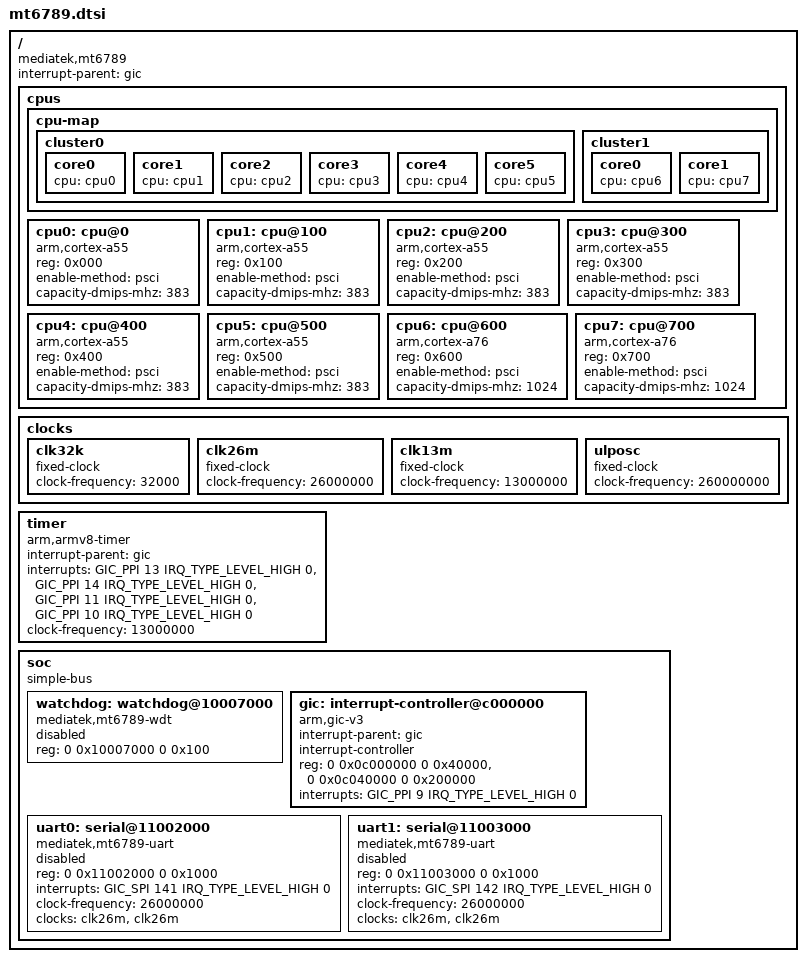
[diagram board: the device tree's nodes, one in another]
//SPDX-License-Identifier: (GPL-2.0)
/*
 * Copyright (C) 2024 Arseniy Velikanov
 */

#include <dt-bindings/interrupt-controller/irq.h>
#include <dt-bindings/interrupt-controller/arm-gic.h>

/ {
	compatible = "mediatek,mt6789";
	interrupt-parent = <&gic>;
	#address-cells = <2>;
	#size-cells = <2>;

	cpus {
		#address-cells = <1>;
		#size-cells = <0>;

		cpu-map {
			cluster0 {
				core0 {
					cpu = <&cpu0>;
				};
				core1 {
					cpu = <&cpu1>;
				};
				core2 {
					cpu = <&cpu2>;
				};
				core3 {
					cpu = <&cpu3>;
				};
                core4 {
                    cpu = <&cpu4>;
                };
                core5 {
                    cpu = <&cpu5>;
                };
			};

			cluster1 {
				core0 {
					cpu = <&cpu6>;
				};
				core1 {
					cpu = <&cpu7>;
				};
			};
		};

		cpu0: cpu@0 {
			device_type = "cpu";
			compatible = "arm,cortex-a55";
			reg = <0x000>;
			enable-method = "psci";
			capacity-dmips-mhz = <383>;
		};

		cpu1: cpu@100 {
			device_type = "cpu";
			compatible = "arm,cortex-a55";
			reg = <0x100>;
			enable-method = "psci";
			capacity-dmips-mhz = <383>;
		};

		cpu2: cpu@200 {
			device_type = "cpu";
			compatible = "arm,cortex-a55";
			reg = <0x200>;
			enable-method = "psci";
			capacity-dmips-mhz = <383>;
		};

		cpu3: cpu@300 {
			device_type = "cpu";
			compatible = "arm,cortex-a55";
			reg = <0x300>;
			enable-method = "psci";
			capacity-dmips-mhz = <383>;
		};

		cpu4: cpu@400 {
			device_type = "cpu";
			compatible = "arm,cortex-a55";
			reg = <0x400>;
			enable-method = "psci";
			capacity-dmips-mhz = <383>;
		};

		cpu5: cpu@500 {
			device_type = "cpu";
			compatible = "arm,cortex-a55";
			reg = <0x500>;
			enable-method = "psci";
			capacity-dmips-mhz = <383>;
		};

		cpu6: cpu@600 {
			device_type = "cpu";
			compatible = "arm,cortex-a76";
			reg = <0x600>;
			enable-method = "psci";
			capacity-dmips-mhz = <1024>;
		};

		cpu7: cpu@700 {
			device_type = "cpu";
			compatible = "arm,cortex-a76";
			reg = <0x700>;
			enable-method = "psci";
			capacity-dmips-mhz = <1024>;
		};
	};

    clocks {
		clk32k: clk32k {
			compatible = "fixed-clock";
			#clock-cells = <0>;
			clock-frequency = <32000>;
		};
		clk26m: clk26m {
			compatible = "fixed-clock";
			#clock-cells = <0>;
			clock-frequency = <26000000>;
		};
		clk13m: clk13m {
			compatible = "fixed-clock";
			#clock-cells = <0>;
			clock-frequency = <13000000>;
		};
		ulposc: ulposc {
			compatible = "fixed-clock";
			#clock-cells = <0>;
			clock-frequency = <260000000>;
		};
	};

    timer {
		compatible = "arm,armv8-timer";
		interrupt-parent = <&gic>;
		interrupts = <GIC_PPI 13 IRQ_TYPE_LEVEL_HIGH 0>,
			         <GIC_PPI 14 IRQ_TYPE_LEVEL_HIGH 0>,
			         <GIC_PPI 11 IRQ_TYPE_LEVEL_HIGH 0>,
			         <GIC_PPI 10 IRQ_TYPE_LEVEL_HIGH 0>;
		clock-frequency = <13000000>;
	};

	soc {
		#address-cells = <2>;
		#size-cells = <2>;
		compatible = "simple-bus";
		ranges;

		watchdog: watchdog@10007000 {
			compatible = "mediatek,mt6789-wdt",
				         "mediatek,wdt";
			reg = <0 0x10007000 0 0x100>;
            #reset-cells = <1>;
			status = "disabled";
		};

		gic: interrupt-controller@c000000 {
			compatible = "arm,gic-v3";
			#interrupt-cells = <4>;
			interrupt-parent = <&gic>;
			interrupt-controller;
			reg = <0 0x0c000000 0 0x40000>,  /* GICD */
			      <0 0x0c040000 0 0x200000>; /* GICR */

			interrupts = <GIC_PPI 9 IRQ_TYPE_LEVEL_HIGH 0>;
		};
	
        uart0: serial@11002000 {
			compatible = "mediatek,mt6789-uart",
				         "mediatek,hsuart";
			reg = <0 0x11002000 0 0x1000>;
			interrupts = <GIC_SPI 141 IRQ_TYPE_LEVEL_HIGH 0>;
			clock-frequency = <26000000>;
			clocks = <&clk26m>, <&clk26m>;
			clock-names = "baud", "bus";
			status = "disabled";
		};

        uart1: serial@11003000 {
			compatible = "mediatek,mt6789-uart",
				         "mediatek,hsuart";
			reg = <0 0x11003000 0 0x1000>;
			interrupts = <GIC_SPI 142 IRQ_TYPE_LEVEL_HIGH 0>;
			clock-frequency = <26000000>;
			clocks = <&clk26m>, <&clk26m>;
			clock-names = "baud", "bus";
			status = "disabled";
		};
    };
};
